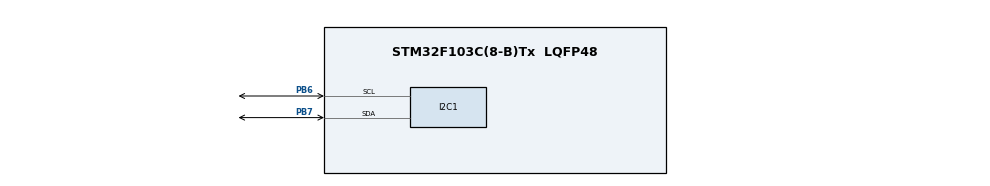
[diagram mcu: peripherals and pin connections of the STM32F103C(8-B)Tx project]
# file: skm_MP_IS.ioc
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Dma.I2C1_TX.0.Direction=DMA_MEMORY_TO_PERIPH
Dma.I2C1_TX.0.Instance=DMA1_Channel6
Dma.I2C1_TX.0.MemDataAlignment=DMA_MDATAALIGN_BYTE
Dma.I2C1_TX.0.MemInc=DMA_MINC_ENABLE
Dma.I2C1_TX.0.Mode=DMA_NORMAL
Dma.I2C1_TX.0.PeriphDataAlignment=DMA_PDATAALIGN_BYTE
Dma.I2C1_TX.0.PeriphInc=DMA_PINC_DISABLE
Dma.I2C1_TX.0.Priority=DMA_PRIORITY_MEDIUM
Dma.Request0=I2C1_TX
I2C1.I2C_Mode=I2C_Fast
Mcu.Family=STM32F1
Mcu.Name=STM32F103C(8-B)Tx
Mcu.Package=LQFP48
NVIC.DMA1_Channel6_IRQn=true\:0\:0\:false\:false\:true\:false\:true\:true
NVIC.I2C1_EV_IRQn=true\:0\:0\:false\:false\:true\:true\:true\:true
NVIC.PriorityGroup=NVIC_PRIORITYGROUP_4
PA13.Mode=Serial_Wire
PA13.Signal=SYS_JTMS-SWDIO
PA14.Mode=Serial_Wire
PA14.Signal=SYS_JTCK-SWCLK
PB6.Mode=I2C
PB6.Signal=I2C1_SCL
PB7.Mode=I2C
PB7.Signal=I2C1_SDA
ProjectManager.HeapSize=0x200
ProjectManager.StackSize=0x400
ProjectManager.TargetToolchain=STM32CubeIDE
RCC.APB1Freq_Value=8000000
RCC.APB2Freq_Value=8000000
board=custom

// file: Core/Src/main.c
/* USER CODE BEGIN Header */
/**
  ******************************************************************************
  * @file           : main.c
  * @brief          : Main program body
  ******************************************************************************
  * @attention
  *
  * Copyright (c) 2023 STMicroelectronics.
  * All rights reserved.
  *
  * This software is licensed under terms that can be found in the LICENSE file
  * in the root directory of this software component.
  * If no LICENSE file comes with this software, it is provided AS-IS.
  *
  ******************************************************************************
  */
/* USER CODE END Header */
#include "main.h"
#include "dma.h"
#include "i2c.h"
#include "gpio.h"

/* USER CODE BEGIN Includes */
#include "ssd1306.h"
#include "fonts.h"
#include "test.h"

/* USER CODE END Includes */

/* USER CODE BEGIN PV */
extern char epd_bitmap_logov1 [];
extern char epd_bitmap_logov2 [];
extern char epd_bitmap_logov3 [];
extern char epd_bitmap_logov4 [];
/* USER CODE END PV */

void SystemClock_Config(void);

int main(void)
{

  /* MCU Configuration--------------------------------------------------------*/

  /* Reset of all peripherals, Initializes the Flash interface and the Systick. */
  HAL_Init();

  /* Configure the system clock */
  SystemClock_Config();

  /* Initialize all configured peripherals */
  MX_GPIO_Init();
  MX_DMA_Init();
  MX_I2C1_Init();
  /* USER CODE BEGIN 2 */

  SSD1306_Init (); // initialize the display

/*
  SSD1306_GotoXY (10,10); // goto 10, 10
  SSD1306_Puts ("Test", &Font_11x18, 1); // print Hello
  SSD1306_GotoXY (10, 30);
  SSD1306_Puts ("DMa_jest", &Font_11x18, 1);
  SSD1306_UpdateScreen(); // update screen
*/

  SSD1306_Clear();
  //SSD1306_DrawBitmap(0, 0, epd_bitmap_Logo_WIET_2021, 128, 64, 1);
  SSD1306_UpdateScreen();

  /* USER CODE END 2 */

  /* Infinite loop */
  while (1)
  {

    /* USER CODE BEGIN 3 */\
//	  SSD1306_Clear();
//	  SSD1306_GotoXY (10,10); // goto 10, 10
//	  SSD1306_Puts ("Test", &Font_11x18, 1); // print Hello
//	  SSD1306_GotoXY (10, 30);
//	  SSD1306_Puts ("", &Font_11x18, 1);
//	  SSD1306_UpdateScreen(); // update screen
//
//	  HAL_Delay(1000);
//	  SSD1306_Clear();
//	  SSD1306_GotoXY (10,10); // goto 10, 10
//	  SSD1306_Puts ("Working", &Font_11x18, 1); // print Hello
//	  SSD1306_GotoXY (10, 30);
//	  SSD1306_Puts ("", &Font_11x18, 1);
//	  SSD1306_UpdateScreen(); // update screen
//
//	  HAL_Delay(5000);

	SSD1306_Clear();
    SSD1306_DrawBitmap(0, 0, epd_bitmap_logov1, 128, 64, 1);
    SSD1306_UpdateScreen();
    HAL_Delay(2000);

    SSD1306_Clear();
    SSD1306_DrawBitmap(0, 0, epd_bitmap_logov2, 128, 64, 1);
    SSD1306_UpdateScreen();
    HAL_Delay(2000);

    SSD1306_Clear();
    SSD1306_DrawBitmap(0, 0, epd_bitmap_logov3, 128, 64, 1);
    SSD1306_UpdateScreen();
    HAL_Delay(2000);

    SSD1306_Clear();
    SSD1306_DrawBitmap(0, 0, epd_bitmap_logov4, 128, 64, 1);
    SSD1306_UpdateScreen();
    HAL_Delay(2000);
  }
  /* USER CODE END 3 */
}

void SystemClock_Config(void)
{
  RCC_OscInitTypeDef RCC_OscInitStruct = {0};
  RCC_ClkInitTypeDef RCC_ClkInitStruct = {0};

  /** Initializes the RCC Oscillators according to the specified parameters
  * in the RCC_OscInitTypeDef structure.
  */
  RCC_OscInitStruct.OscillatorType = RCC_OSCILLATORTYPE_HSI;
  RCC_OscInitStruct.HSIState = RCC_HSI_ON;
  RCC_OscInitStruct.HSICalibrationValue = RCC_HSICALIBRATION_DEFAULT;
  RCC_OscInitStruct.PLL.PLLState = RCC_PLL_NONE;
  if (HAL_RCC_OscConfig(&RCC_OscInitStruct) != HAL_OK)
  {
    Error_Handler();
  }

  /** Initializes the CPU, AHB and APB buses clocks
  */
  RCC_ClkInitStruct.ClockType = RCC_CLOCKTYPE_HCLK|RCC_CLOCKTYPE_SYSCLK
                              |RCC_CLOCKTYPE_PCLK1|RCC_CLOCKTYPE_PCLK2;
  RCC_ClkInitStruct.SYSCLKSource = RCC_SYSCLKSOURCE_HSI;
  RCC_ClkInitStruct.AHBCLKDivider = RCC_SYSCLK_DIV1;
  RCC_ClkInitStruct.APB1CLKDivider = RCC_HCLK_DIV1;
  RCC_ClkInitStruct.APB2CLKDivider = RCC_HCLK_DIV1;

  if (HAL_RCC_ClockConfig(&RCC_ClkInitStruct, FLASH_LATENCY_0) != HAL_OK)
  {
    Error_Handler();
  }
}

void Error_Handler(void)
{
  __disable_irq();
  while (1)
  {
  }
}
